VERSION "1.0"

NS_ :

BS_:

BU_: BC BRK

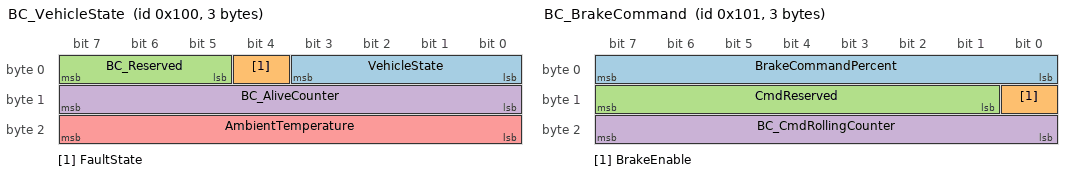
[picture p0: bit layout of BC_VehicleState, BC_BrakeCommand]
BO_ 256 BC_VehicleState: 3 BC
 SG_ VehicleState : 0|4@1+ (1,0) [0|3] "" BRK
 SG_ FaultState : 4|1@1+ (1,0) [0|1] "" BRK
 SG_ BC_Reserved : 5|3@1+ (1,0) [0|7] "" BRK
 SG_ BC_AliveCounter : 8|8@1+ (1,0) [0|255] "count" BRK
 SG_ AmbientTemperature : 16|8@1- (1,0) [-40|85] "degC" BRK

BO_ 257 BC_BrakeCommand: 3 BC
 SG_ BrakeCommandPercent : 0|8@1+ (1,0) [0|100] "%" BRK
 SG_ BrakeEnable : 8|1@1+ (1,0) [0|1] "" BRK
 SG_ CmdReserved : 9|7@1+ (1,0) [0|127] "" BRK
 SG_ BC_CmdRollingCounter : 16|8@1+ (1,0) [0|255] "count" BRK

VAL_ 256 VehicleState 0 "OFF" 1 "STARTUP" 2 "READY" 3 "SHUTDOWN" ;
VAL_ 256 FaultState 0 "Normal" 1 "FaultActive" ;
VAL_ 257 BrakeEnable 0 "Disabled" 1 "Enabled" ;
